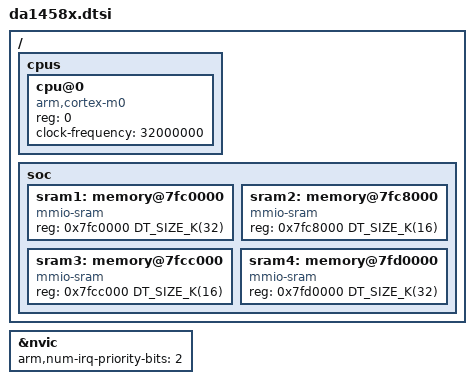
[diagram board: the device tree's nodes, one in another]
#include <arm/armv6-m.dtsi>
#include <mem.h>
#include <freq.h>

/ {
	cpus: cpus {
		#address-cells = <1>;
		#size-cells = <0>;

		cpu@0 {
			compatible = "arm,cortex-m0";
			reg = <0>;
			clock-frequency = <32000000>;
		};
	};

	soc {
		sram1: memory@7fc0000 {
			compatible = "mmio-sram";
			reg = <0x7fc0000 DT_SIZE_K(32)>;
		};
		sram2: memory@7fc8000 {
			compatible = "mmio-sram";
			reg = <0x7fc8000 DT_SIZE_K(16)>;
		};
		sram3: memory@7fcc000 {
			compatible = "mmio-sram";
			reg = <0x7fcc000 DT_SIZE_K(16)>;
		};
		sram4: memory@7fd0000 {
			compatible = "mmio-sram";
			reg = <0x7fd0000 DT_SIZE_K(32)>;
		};
	};
};

&nvic {
	arm,num-irq-priority-bits = <2>;
};
